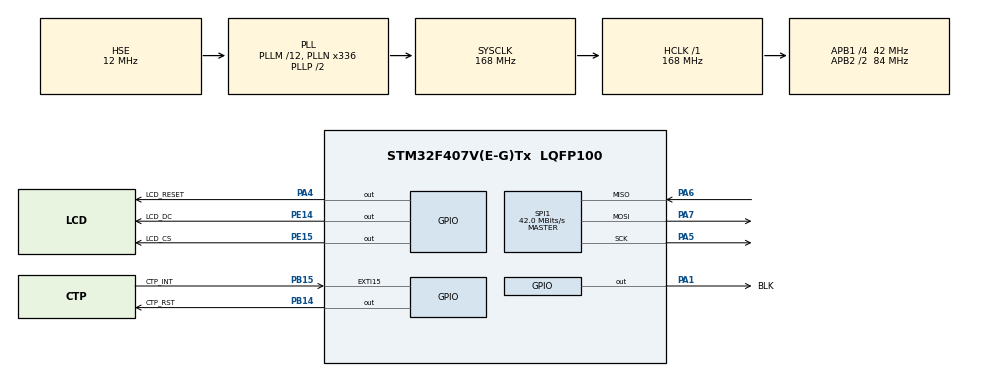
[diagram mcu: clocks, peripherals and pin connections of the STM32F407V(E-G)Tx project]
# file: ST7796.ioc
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Dma.Request0=SPI1_TX
Dma.SPI1_TX.0.Direction=DMA_MEMORY_TO_PERIPH
Dma.SPI1_TX.0.FIFOMode=DMA_FIFOMODE_DISABLE
Dma.SPI1_TX.0.Instance=DMA2_Stream3
Dma.SPI1_TX.0.MemDataAlignment=DMA_MDATAALIGN_BYTE
Dma.SPI1_TX.0.MemInc=DMA_MINC_ENABLE
Dma.SPI1_TX.0.Mode=DMA_NORMAL
Dma.SPI1_TX.0.PeriphDataAlignment=DMA_PDATAALIGN_BYTE
Dma.SPI1_TX.0.PeriphInc=DMA_PINC_DISABLE
Dma.SPI1_TX.0.Priority=DMA_PRIORITY_HIGH
Mcu.Family=STM32F4
Mcu.Name=STM32F407V(E-G)Tx
Mcu.Package=LQFP100
NVIC.DMA2_Stream3_IRQn=true\:0\:0\:false\:false\:true\:false\:true\:true
NVIC.EXTI15_10_IRQn=true\:0\:0\:false\:false\:true\:true\:true\:true
NVIC.PriorityGroup=NVIC_PRIORITYGROUP_4
NVIC.SPI1_IRQn=true\:5\:0\:true\:false\:true\:true\:true\:true
PA1.GPIO_Label=BLK
PA1.Signal=GPIO_Output
PA13.Mode=Serial_Wire
PA13.Signal=SYS_JTMS-SWDIO
PA14.Mode=Serial_Wire
PA14.Signal=SYS_JTCK-SWCLK
PA4.GPIO_Label=LCD_RESET
PA4.GPIO_PuPd=GPIO_PULLUP
PA4.GPIO_Speed=GPIO_SPEED_FREQ_VERY_HIGH
PA4.Signal=GPIO_Output
PA5.GPIO_PuPd=GPIO_PULLUP
PA5.Mode=Full_Duplex_Master
PA5.Signal=SPI1_SCK
PA6.GPIO_PuPd=GPIO_PULLUP
PA6.Mode=Full_Duplex_Master
PA6.Signal=SPI1_MISO
PA7.GPIO_PuPd=GPIO_PULLUP
PA7.Mode=Full_Duplex_Master
PA7.Signal=SPI1_MOSI
PB14.GPIO_Label=CTP_RST
PB14.Signal=GPIO_Output
PB15.GPIO_Label=CTP_INT
PB15.Signal=GPXTI15
PE14.GPIO_Label=LCD_DC
PE14.Signal=GPIO_Output
PE15.GPIO_Label=LCD_CS
PE15.Signal=GPIO_Output
PH0-OSC_IN.Mode=HSE-External-Oscillator
PH0-OSC_IN.Signal=RCC_OSC_IN
PH1-OSC_OUT.Mode=HSE-External-Oscillator
PH1-OSC_OUT.Signal=RCC_OSC_OUT
ProjectManager.HeapSize=0x400
ProjectManager.StackSize=0x400
ProjectManager.TargetToolchain=MDK-ARM V5.32
RCC.48MHZClocksFreq_Value=48000000
RCC.AHBFreq_Value=168000000
RCC.APB1CLKDivider=RCC_HCLK_DIV4
RCC.APB1Freq_Value=42000000
RCC.APB1TimFreq_Value=84000000
RCC.APB2CLKDivider=RCC_HCLK_DIV2
RCC.APB2Freq_Value=84000000
RCC.APB2TimFreq_Value=168000000
RCC.CortexFreq_Value=168000000
RCC.HCLKFreq_Value=168000000
RCC.HSE_VALUE=12000000
RCC.HSI_VALUE=16000000
RCC.LSE_VALUE=32768
RCC.PLLM=12
RCC.PLLN=336
RCC.PLLQ=7
RCC.PLLSourceVirtual=RCC_PLLSOURCE_HSE
RCC.SYSCLKFreq_VALUE=168000000
RCC.SYSCLKSource=RCC_SYSCLKSOURCE_PLLCLK
RCC.VCOOutputFreq_Value=336000000
SPI1.BaudRatePrescaler=SPI_BAUDRATEPRESCALER_2
SPI1.CLKPhase=SPI_PHASE_1EDGE
SPI1.CLKPolarity=SPI_POLARITY_LOW
SPI1.CalculateBaudRate=42.0 MBits/s
SPI1.Direction=SPI_DIRECTION_2LINES
SPI1.Mode=SPI_MODE_MASTER
SPI1.VirtualType=VM_MASTER
VP_CRC_VS_CRC.Mode=CRC_Activate
board=custom

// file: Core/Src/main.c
/* USER CODE BEGIN Header */
/**
  ******************************************************************************
  * @file           : main.c
  * @brief          : Main program body
    @brief          : SAEED KOLIVAND
  ******************************************************************************
  * @attention
  *
  * Copyright (c) 2024 STMicroelectronics.
  * All rights reserved.
  *
  * This software is licensed under terms that can be found in the LICENSE file
  * in the root directory of this software component.
  * If no LICENSE file comes with this software, it is provided AS-IS.
  *
  ******************************************************************************
  */
/* USER CODE END Header */
#include "main.h"
#include "crc.h"
#include "dma.h"
#include "spi.h"
#include "gpio.h"

/* USER CODE BEGIN Includes */
#include "ST7796.h"
/* USER CODE END Includes */

void SystemClock_Config(void);

int main(void)
{

  /* MCU Configuration--------------------------------------------------------*/

  /* Reset of all peripherals, Initializes the Flash interface and the Systick. */
  HAL_Init();

  /* Configure the system clock */
  SystemClock_Config();

  /* Initialize all configured peripherals */
  MX_GPIO_Init();
  MX_DMA_Init();
  MX_SPI1_Init();
  MX_CRC_Init();
  /* USER CODE BEGIN 2 */

  HAL_GPIO_WritePin(GPIOA, BLK_Pin, GPIO_PIN_SET);   /* backlight on */

   HAL_Delay(100);
    ST7796_SPI_Init();   /* initial LCD */
     HAL_Delay(120);
      ST7796_Set_Rotation(2);   /* Rotation LCD */
        ST7796_Fill_Screen(RED);

           ST7796_Draw_Text("PEPOYA.ir", 10, 10, BLACK, 2 , RED);

  /* USER CODE END 2 */

  /* Infinite loop */
  while (1)
  {

  }
}

void SystemClock_Config(void)
{
  RCC_OscInitTypeDef RCC_OscInitStruct = {0};
  RCC_ClkInitTypeDef RCC_ClkInitStruct = {0};

  /** Configure the main internal regulator output voltage
  */
  __HAL_RCC_PWR_CLK_ENABLE();
  __HAL_PWR_VOLTAGESCALING_CONFIG(PWR_REGULATOR_VOLTAGE_SCALE1);

  /** Initializes the RCC Oscillators according to the specified parameters
  * in the RCC_OscInitTypeDef structure.
  */
  RCC_OscInitStruct.OscillatorType = RCC_OSCILLATORTYPE_HSE;
  RCC_OscInitStruct.HSEState = RCC_HSE_ON;
  RCC_OscInitStruct.PLL.PLLState = RCC_PLL_ON;
  RCC_OscInitStruct.PLL.PLLSource = RCC_PLLSOURCE_HSE;
  RCC_OscInitStruct.PLL.PLLM = 12;
  RCC_OscInitStruct.PLL.PLLN = 336;
  RCC_OscInitStruct.PLL.PLLP = RCC_PLLP_DIV2;
  RCC_OscInitStruct.PLL.PLLQ = 7;
  if (HAL_RCC_OscConfig(&RCC_OscInitStruct) != HAL_OK)
  {
    Error_Handler();
  }

  /** Initializes the CPU, AHB and APB buses clocks
  */
  RCC_ClkInitStruct.ClockType = RCC_CLOCKTYPE_HCLK|RCC_CLOCKTYPE_SYSCLK
                                |RCC_CLOCKTYPE_PCLK1|RCC_CLOCKTYPE_PCLK2;
  RCC_ClkInitStruct.SYSCLKSource = RCC_SYSCLKSOURCE_PLLCLK;
  RCC_ClkInitStruct.AHBCLKDivider = RCC_SYSCLK_DIV1;
  RCC_ClkInitStruct.APB1CLKDivider = RCC_HCLK_DIV4;
  RCC_ClkInitStruct.APB2CLKDivider = RCC_HCLK_DIV2;

  if (HAL_RCC_ClockConfig(&RCC_ClkInitStruct, FLASH_LATENCY_5) != HAL_OK)
  {
    Error_Handler();
  }
}

void Error_Handler(void)
{
  __disable_irq();
  while (1)
  {
  }
}
